# YT9215 register map
Vendor: Motorcomm; Series: YT921x; File version: 1.0
Registers are 32-bit, read-write, no defined reset value unless marked. A register's access mark holds for its fields unless they carry their own. Offsets are from the block's base; [hi:lo] are bit positions; {n}, {i} and the like mark numbered series; 'fields as' and 'values as' point back to an identical list.

## GLOBAL — Global control and port MACs
Base 0x00080000
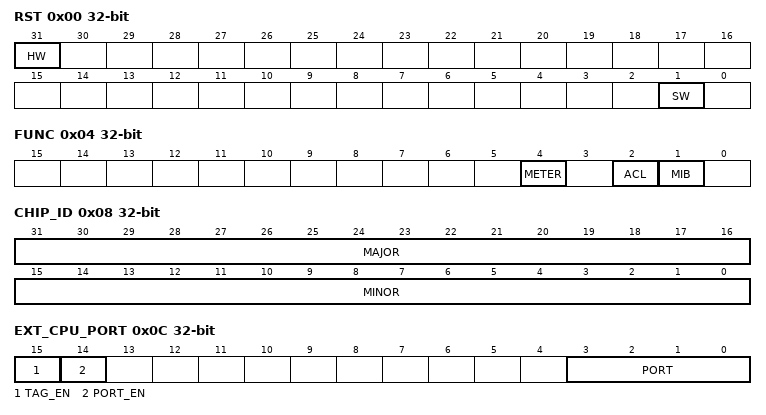
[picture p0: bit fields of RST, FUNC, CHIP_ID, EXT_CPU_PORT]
0x00 RST — Starts a reset of the switch. Write RST.HW and poll the register until it reads 0; Reset gives the full sequence.
  [31] HW — Write 1 to reset the whole chip. The bit clears itself when the reset is complete. Section 4.1.2.1 of the YT9215SCH datasheet calls the bit CHIP_RESET.
  [1] SW — Write 1 for a software reset. Section 4.1.2.2 of the YT9215SCH datasheet calls the bit SW_RESET. It states that the bit clears itself and resets what RST.HW resets except the analog circuit of the built-in PHYs. No function of the Linux driver uses the bit.
0x04 FUNC — Enable bits of three function blocks. :ref:`bringup-features` gives the evidence for their effect. The vendor SDK names a fourth enable bit, AC_EN in bit 3, which this manual does not describe.
  [4] METER — Enable bit of the meters, whose registers are METER_CTRL and PORT_METER. yt921x_chip_setup sets the bit, and the vendor SDK function fal_tiger_rate_init() writes it as an enable. It is inferred that the block works only while the bit is set.
  [2] ACL — Enable bit of the access control list, whose registers include ACL_KEY and ACL_ACT. yt921x_chip_setup sets the bit, and the vendor SDK function fal_tiger_acl_global_enable() writes it as an enable. It is inferred that the block works only while the bit is set.
  [1] MIB — Enable bit of the port counters of MIB_DATA. yt921x_chip_setup sets the bit, and the vendor SDK function fal_tiger_stat_mib_enable_set() writes it as an enable. It is inferred that the block works only while the bit is set.
0x08 CHIP_ID ro — Identifies the chip family. Read it before the reset, as described in Find the switch.
  [31:16] MAJOR — Family code. 0x9002 is the YT9215 family and 0x9001 the YT9218 family.
  [15:0] MINOR — Lower half of the chip ID. The file fal_tiger_init.c of the vendor SDK tests it for the value 1. The meaning of its values is not known.
0x0C EXT_CPU_PORT — Names the port that leads to the host CPU and turns CPU tagging on for it; see CPU port and frame tag.
  [15] TAG_EN — Frames to and from the CPU port carry the 8-byte CPU tag.
  [14] PORT_EN — EXT_CPU_PORT.PORT is valid and that port is treated as the CPU port.
  [3:0] PORT — Number of the CPU port from 0 to 10.
0x10 CPU_TAG_TPID reset 0x9988 — EtherType that opens the CPU tag. Reading the reset value back is a cheap check that register access works.
  [15:0] TPID — EtherType of the CPU tag.
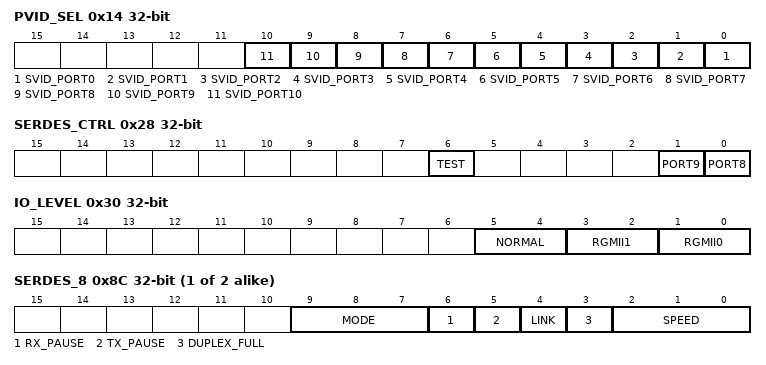
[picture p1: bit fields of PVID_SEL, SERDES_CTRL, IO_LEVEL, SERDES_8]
0x14 PVID_SEL — Chooses, per port, which VLAN tag selects the VLAN table entry.
  [n] SVID_PORT{n} (n=0..10) — Port port looks frames up by the service VLAN ID. It does not use the customer VLAN ID.
0x28 SERDES_CTRL — Enables the SGMII SerDes of ports 8 and 9, as yt921x_port_config does. A port uses either its SerDes or its xMII pins; clear the matching bit in XMII_CTRL when setting one here.
  [6] TEST — yt921x_chip_setup clears the bit. It is inferred from the name that the bit selects a test mode of the SerDes. The file fal_tiger_init.c of the vendor SDK clears the bit together with the two port bits under a comment with the lines "disable sds intf,will be enabled when config sds mode" and "set to mdio access mode".
  [n-8] PORT{n} (n=8..9) — Bit 0 enables the SerDes of port 8. Bit 1 enables the SerDes of port 9.
0x30 IO_LEVEL — Sets the signalling voltage of the digital pins. The field positions differ between the YT9215 and YT9218 families.
  [5:4] NORMAL — Voltage of the general digital I/O pins.
    0=V3V3 (3.3 V); 3=V1V8 (1.8 V)
  [3:2] RGMII1 — Voltage of the second xMII interface pins.
    0=V3V3 (3.3 V); 1=V2V5 (2.5 V); 2=V1V8 (1.8 V)
  [1:0] RGMII0 — Voltage of the first xMII interface pins.
    0=V3V3 (3.3 V); 1=V2V5 (2.5 V); 2=V1V8 (1.8 V)
0x80 MAC_ADDR_HI2 — Two bytes of the MAC address of the switch. It is inferred from the name that the switch uses the address as the source address of frames it sends itself, such as pause frames. :ref:`bringup-mac` gives the two readings of the byte order.
  [15:0] ADDR — Two bytes of the MAC address. The register name reads as the first two bytes of the address, which is inferred. The vendor SDK reads the field as the last two bytes, with byte 4 in bits 15 to 8. It is not known which is right.
0x84 MAC_ADDR_LO4 — Four bytes of the MAC address of the switch; see MAC_ADDR_HI2.
  [31:0] ADDR — Four bytes of the MAC address. The register name reads as the last four bytes of the address, which is inferred. The vendor SDK reads the field as the first four bytes, with byte 0 in bits 31 to 24. It is not known which is right.
{0x6C+4i} SERDES_{i} (i=8..9) — Protocol of one SerDes and, when the link is not negotiated in-band, its forced link settings. The SerDes PCS registers themselves are standard MDIO registers reached through the internal MDIO master at the address of the port number. Index: port = 8 to 9.
  [9:7] MODE — SerDes protocol.
    0=SGMII (SGMII as the MAC side); 1=REVSGMII (SGMII as the PHY side); 2=V1000BASEX (1000BASE-X); 3=V100BASEX (100BASE-FX fibre mode); 4=V2500BASEX (2500BASE-X)
  [6] RX_PAUSE — Forced receive pause.
  [5] TX_PAUSE — Forced transmit pause.
  [4] LINK — Forces the link up.
  [3] DUPLEX_FULL — Forced full duplex.
  [2:0] SPEED — Forced speed.
    0=V10 (10 Mbit/s); 1=V100 (100 Mbit/s); 2=V1000 (1000 Mbit/s); 3=V10000 (10000 Mbit/s); 4=V2500 (2500 Mbit/s)
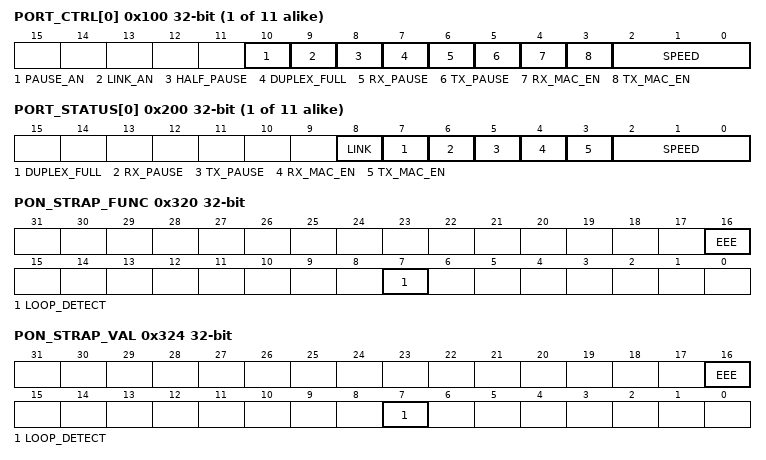
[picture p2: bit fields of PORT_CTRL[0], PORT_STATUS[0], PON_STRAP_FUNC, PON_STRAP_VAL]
{0x100+4i} PORT_CTRL[{i}] (i=0..10) — Forces or negotiates the MAC settings of one port. Bits 7 to 0 have the same layout as PORT_STATUS; it is inferred from the name of PORT_CTRL.LINK_AN that with the bit clear the MAC uses the values written here. Bring a port up gives the order of writes. Index: port = 0 to 10.
  [10] PAUSE_AN — yt921x_serdes_config sets the bit for a SerDes link with in-band negotiation other than SGMII whose pause result the MAC may take. It is inferred from the name that the MAC then takes the pause settings from in-band negotiation and ignores PORT_CTRL.RX_PAUSE and PORT_CTRL.TX_PAUSE.
  [9] LINK_AN — yt921x_serdes_config sets the bit for a SerDes link with in-band status. It is inferred from the name that the MAC then takes speed and duplex from the in-band status, that the bit also follows a built-in PHY and that the forced bits are then ignored.
  [8] HALF_PAUSE — Use back pressure for flow control in half duplex.
  [7] DUPLEX_FULL — Forced full duplex.
  [6] RX_PAUSE — Honour received pause frames.
  [5] TX_PAUSE — Send pause frames when the port is congested.
  [4] RX_MAC_EN — Enables the receive side of the MAC.
  [3] TX_MAC_EN — Enables the transmit side of the MAC.
  [2:0] SPEED — Forced speed.
    values as SERDES_8.SPEED
{0x200+4i} PORT_STATUS[{i}] (i=0..10) ro — Link state and the MAC settings one port is running with. Index: port = 0 to 10.
  [8] LINK — 1 while the link is up.
  [7] DUPLEX_FULL — 1 for full duplex.
  [6] RX_PAUSE — Receive pause is active.
  [5] TX_PAUSE — Transmit pause is active.
  [4] RX_MAC_EN — The receive side of the MAC is enabled.
  [3] TX_MAC_EN — The transmit side of the MAC is enabled.
  [2:0] SPEED — Current speed.
    values as SERDES_8.SPEED
0x320 PON_STRAP_FUNC — Selects, per function, whether the switch uses the level sampled on the strap pin at power-on (bit clear) or the value in PON_STRAP_VAL (bit set). This split between the two registers is inferred from their names. yt921x_set_eee writes the same value to the EEE bit of both.
  [16] EEE — Take the Energy Efficient Ethernet setting from PON_STRAP_VAL.EEE. yt921x_set_eee sets this bit together with PON_STRAP_VAL.EEE to turn the function on; the role of each bit alone is inferred from the register names.
  [7] LOOP_DETECT — Take the loop detection setting from PON_STRAP_VAL.LOOP_DETECT.
0x324 PON_STRAP_VAL — It is inferred from the register names that the switch uses these values in place of the power-on straps for every function whose bit is set in PON_STRAP_FUNC.
  [16] EEE — 1 turns Energy Efficient Ethernet on. yt921x_set_eee sets this bit together with PON_STRAP_FUNC.EEE; the role of each bit alone is inferred from the register names.
  [7] LOOP_DETECT — Loop detection strap value. The vendor SDK function fal_tiger_loop_detect_enable_set() clears this bit and sets PON_STRAP_FUNC.LOOP_DETECT to turn loop detection on, and its comment calls the strap "dis lpd strap". By that code 1 turns loop detection off.
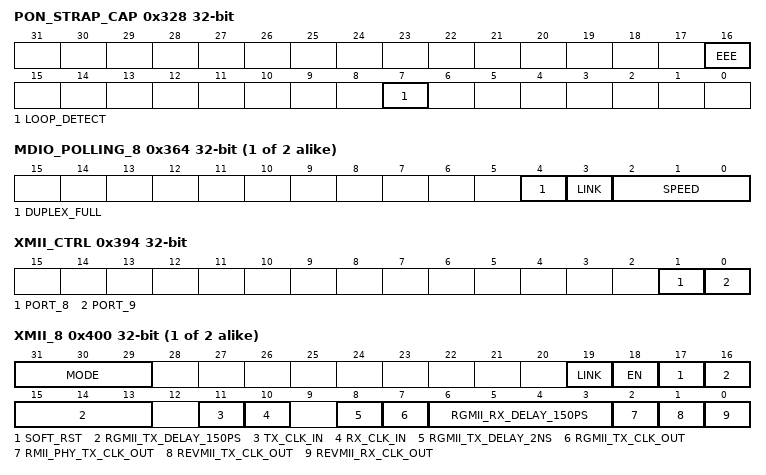
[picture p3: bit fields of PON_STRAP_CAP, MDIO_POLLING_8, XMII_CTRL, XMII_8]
0x328 PON_STRAP_CAP ro — Levels that were sampled on the strap pins at power-on.
  [16] EEE — Captured Energy Efficient Ethernet strap.
  [7] LOOP_DETECT — Captured loop detection strap.
{0x344+4i} MDIO_POLLING_{i} (i=8..9) — Link state of port 8 or 9. yt921x_port_up writes the link state here for an external port that does not use its SerDes. It is inferred from the name that the switch otherwise learns the state by polling a PHY on the external MDIO bus. Index: port = 8 to 9.
  [4] DUPLEX_FULL — 1 for full duplex.
  [3] LINK — 1 for link up.
  [2:0] SPEED — Link speed.
    values as SERDES_8.SPEED
0x36C SENSOR — Enables the on-chip sensors.
  [18] TEMP — Enables the temperature sensor that TEMP reads.
0x374 TEMP ro — Reading of the temperature sensor. No function of the Linux driver reads the register. :ref:`bringup-temp` gives the conversion that the vendor SDK uses.
  [31:0] VALUE — Sensor value. The vendor SDK function fal_tiger_sensor_temp_value_get() uses bits 15 to 0, in steps of 1/128 °C.
0x388 CHIP_MODE ro — Tells the parts of one family apart. :ref:`reference-parts` lists the value of each part.
  [1:0] MODE — Package variant code.
0x394 XMII_CTRL — Selects the parallel MAC interface (MII, RMII or RGMII) pins of ports 8 and 9. The bit order is the reverse of the port order. yt921x_port_config clears the bit of a port that uses its SerDes. The vendor SDK function fal_tiger_port_extif_mode_set() sets the bit for an xMII mode, under the comment "select xmii mode".
  [1] PORT_8 — Bit 1 selects the xMII pins of port 8. Bit 0 selects the xMII pins of port 9.
  [0] PORT_9 — Bit 1 selects the xMII pins of port 8. Bit 0 selects the xMII pins of port 9.
{0x3C0+8i} XMII_{i} (i=8..9) — Mode, clock direction and RGMII delays of one parallel MAC interface. Index: port = 8 to 9.
  [31:29] MODE — Interface type.
    0=MII (MII as the MAC side); 1=REVMII (MII as the PHY side); 2=RMII (RMII as the MAC side); 3=REVRMII (RMII as the PHY side); 4=RGMII; 5=DISABLE (Interface off)
  [19] LINK — Forces the link of the interface up.
  [18] EN — Enables the interface.
  [17] SOFT_RST — Resets the interface logic.
  [16:13] RGMII_TX_DELAY_150PS — Fine RGMII transmit clock delay in steps of 150 ps. A comment in fal_tiger_port.c of the vendor SDK gives the transmit clock delay as 2 ns times XMII.RGMII_TX_DELAY_2NS plus 0.15 ns times this field.
  [11] TX_CLK_IN — The Linux name reads as: the transmit clock pin is an input. The vendor SDK names the bit XMII_TXC_IN_SEL, and its function fal_tiger_port_extif_xmiiClk_invert_set() writes the bit as the enable of an inverted xMII clock. The two readings disagree, and it is not known which is right.
  [10] RX_CLK_IN — The receive clock pin is an input.
  [8] RGMII_TX_DELAY_2NS — Adds 2 ns to the delay of the RGMII transmit clock, by the comment in fal_tiger_port.c of the vendor SDK.
  [7] RGMII_TX_CLK_OUT — Drives the RGMII transmit clock.
  [6:3] RGMII_RX_DELAY_150PS — RGMII receive clock delay in steps of 150 ps, by the comment in fal_tiger_port.c of the vendor SDK.
  [2] RMII_PHY_TX_CLK_OUT — Drives the RMII reference clock when the switch is the PHY side.
  [1] REVMII_TX_CLK_OUT — Drives the MII transmit clock when the switch is the PHY side.
  [0] REVMII_RX_CLK_OUT — Drives the MII receive clock when the switch is the PHY side.
{0x1008+0x1000*i} MAC_FRAME[{i}] (i=0..10) — Largest frame the MAC of one port accepts. Index: port = 0 to 10.
  [21:8] SIZE — Maximum frame length in bytes. The length counts from the destination address to the frame check sequence. The largest value is 0x2400 (9216).
